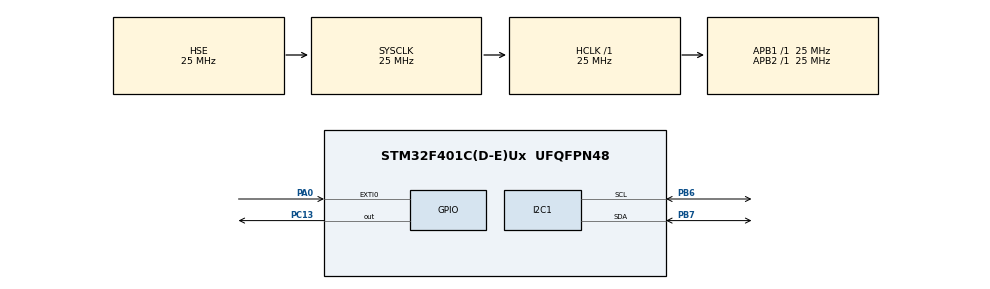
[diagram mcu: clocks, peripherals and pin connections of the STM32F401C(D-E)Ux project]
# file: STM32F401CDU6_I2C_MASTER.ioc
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Mcu.Family=STM32F4
Mcu.Name=STM32F401C(D-E)Ux
Mcu.Package=UFQFPN48
NVIC.EXTI0_IRQn=true\:0\:0\:false\:false\:true\:true\:true\:true
NVIC.I2C1_EV_IRQn=true\:0\:0\:false\:false\:true\:true\:true\:true
NVIC.PriorityGroup=NVIC_PRIORITYGROUP_4
PA0-WKUP.GPIO_ModeDefaultEXTI=GPIO_MODE_IT_RISING
PA0-WKUP.GPIO_PuPd=GPIO_PULLDOWN
PA0-WKUP.Signal=GPXTI0
PA13.Mode=Serial_Wire
PA13.Signal=SYS_JTMS-SWDIO
PA14.Mode=Serial_Wire
PA14.Signal=SYS_JTCK-SWCLK
PB6.Mode=I2C
PB6.Signal=I2C1_SCL
PB7.Mode=I2C
PB7.Signal=I2C1_SDA
PC13-ANTI_TAMP.PinState=GPIO_PIN_SET
PC13-ANTI_TAMP.Signal=GPIO_Output
PH0\ -\ OSC_IN.Mode=HSE-External-Oscillator
PH0\ -\ OSC_IN.Signal=RCC_OSC_IN
PH1\ -\ OSC_OUT.Mode=HSE-External-Oscillator
PH1\ -\ OSC_OUT.Signal=RCC_OSC_OUT
ProjectManager.HeapSize=0x200
ProjectManager.StackSize=0x400
ProjectManager.TargetToolchain=STM32CubeIDE
RCC.AHBFreq_Value=25000000
RCC.APB1Freq_Value=25000000
RCC.APB1TimFreq_Value=25000000
RCC.APB2Freq_Value=25000000
RCC.APB2TimFreq_Value=25000000
RCC.CortexFreq_Value=25000000
RCC.HCLKFreq_Value=25000000
RCC.HSE_VALUE=25000000
RCC.HSI_VALUE=16000000
RCC.LSE_VALUE=32768
RCC.SYSCLKFreq_VALUE=25000000
RCC.SYSCLKSource=RCC_SYSCLKSOURCE_HSE
RCC.VCOOutputFreq_Value=192000000
board=custom

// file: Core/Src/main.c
/* USER CODE BEGIN Header */
/**
  ******************************************************************************
  * @file           : main.c
  * @brief          : Main program body
  ******************************************************************************
  * @attention
  *
  * Copyright (c) 2024 STMicroelectronics.
  * All rights reserved.
  *
  * This software is licensed under terms that can be found in the LICENSE file
  * in the root directory of this software component.
  * If no LICENSE file comes with this software, it is provided AS-IS.
  *
  ******************************************************************************
  */
/* USER CODE END Header */
#include "main.h"

I2C_HandleTypeDef hi2c1;

/* USER CODE BEGIN PV */
static uint8_t data[] = {0x0F, 0x0A};  // Example data to send
static uint16_t DevAddress = 15 << 1;      // 7-bit address shifted for 8-bit format
static uint8_t index = 0;
/* USER CODE END PV */

void SystemClock_Config(void);
static void MX_GPIO_Init(void);
static void MX_I2C1_Init(void);

int main(void)
{

  /* MCU Configuration--------------------------------------------------------*/

  /* Reset of all peripherals, Initializes the Flash interface and the Systick. */
  HAL_Init();

  /* Configure the system clock */
  SystemClock_Config();

  /* Initialize all configured peripherals */
  MX_GPIO_Init();
  MX_I2C1_Init();

  /* Infinite loop */
  while (1)
  {

  }
}

void SystemClock_Config(void)
{
  RCC_OscInitTypeDef RCC_OscInitStruct = {0};
  RCC_ClkInitTypeDef RCC_ClkInitStruct = {0};

  /** Configure the main internal regulator output voltage
  */
  __HAL_RCC_PWR_CLK_ENABLE();
  __HAL_PWR_VOLTAGESCALING_CONFIG(PWR_REGULATOR_VOLTAGE_SCALE2);

  /** Initializes the RCC Oscillators according to the specified parameters
  * in the RCC_OscInitTypeDef structure.
  */
  RCC_OscInitStruct.OscillatorType = RCC_OSCILLATORTYPE_HSE;
  RCC_OscInitStruct.HSEState = RCC_HSE_ON;
  RCC_OscInitStruct.PLL.PLLState = RCC_PLL_NONE;
  if (HAL_RCC_OscConfig(&RCC_OscInitStruct) != HAL_OK)
  {
    Error_Handler();
  }

  /** Initializes the CPU, AHB and APB buses clocks
  */
  RCC_ClkInitStruct.ClockType = RCC_CLOCKTYPE_HCLK|RCC_CLOCKTYPE_SYSCLK
                              |RCC_CLOCKTYPE_PCLK1|RCC_CLOCKTYPE_PCLK2;
  RCC_ClkInitStruct.SYSCLKSource = RCC_SYSCLKSOURCE_HSE;
  RCC_ClkInitStruct.AHBCLKDivider = RCC_SYSCLK_DIV1;
  RCC_ClkInitStruct.APB1CLKDivider = RCC_HCLK_DIV1;
  RCC_ClkInitStruct.APB2CLKDivider = RCC_HCLK_DIV1;

  if (HAL_RCC_ClockConfig(&RCC_ClkInitStruct, FLASH_LATENCY_0) != HAL_OK)
  {
    Error_Handler();
  }
}

static void MX_I2C1_Init(void)
{

  hi2c1.Instance = I2C1;
  hi2c1.Init.ClockSpeed = 100000;
  hi2c1.Init.DutyCycle = I2C_DUTYCYCLE_2;
  hi2c1.Init.OwnAddress1 = 0;
  hi2c1.Init.AddressingMode = I2C_ADDRESSINGMODE_7BIT;
  hi2c1.Init.DualAddressMode = I2C_DUALADDRESS_DISABLE;
  hi2c1.Init.OwnAddress2 = 0;
  hi2c1.Init.GeneralCallMode = I2C_GENERALCALL_DISABLE;
  hi2c1.Init.NoStretchMode = I2C_NOSTRETCH_DISABLE;
  if (HAL_I2C_Init(&hi2c1) != HAL_OK)
  {
    Error_Handler();
  }

}

static void MX_GPIO_Init(void)
{
  GPIO_InitTypeDef GPIO_InitStruct = {0};

  /* GPIO Ports Clock Enable */
  __HAL_RCC_GPIOC_CLK_ENABLE();
  __HAL_RCC_GPIOH_CLK_ENABLE();
  __HAL_RCC_GPIOA_CLK_ENABLE();
  __HAL_RCC_GPIOB_CLK_ENABLE();

  /*Configure GPIO pin Output Level */
  HAL_GPIO_WritePin(GPIOC, GPIO_PIN_13, GPIO_PIN_SET);

  /*Configure GPIO pin : PC13 */
  GPIO_InitStruct.Pin = GPIO_PIN_13;
  GPIO_InitStruct.Mode = GPIO_MODE_OUTPUT_PP;
  GPIO_InitStruct.Pull = GPIO_NOPULL;
  GPIO_InitStruct.Speed = GPIO_SPEED_FREQ_LOW;
  HAL_GPIO_Init(GPIOC, &GPIO_InitStruct);

  /*Configure GPIO pin : PA0 */
  GPIO_InitStruct.Pin = GPIO_PIN_0;
  GPIO_InitStruct.Mode = GPIO_MODE_IT_RISING;
  GPIO_InitStruct.Pull = GPIO_PULLDOWN;
  HAL_GPIO_Init(GPIOA, &GPIO_InitStruct);

  /* EXTI interrupt init*/
  HAL_NVIC_SetPriority(EXTI0_IRQn, 0, 0);
  HAL_NVIC_EnableIRQ(EXTI0_IRQn);

}

/* USER CODE BEGIN 4 */
/* HAL callback function for EXTI line 0 (PA0) */
void HAL_GPIO_EXTI_Callback(uint16_t GPIO_Pin) {
    if (GPIO_Pin == GPIO_PIN_0) {
    	HAL_GPIO_TogglePin(GPIOC, GPIO_PIN_13);
    	index %= 2;
    	HAL_I2C_Master_Transmit(&hi2c1, DevAddress, (uint8_t*)data, (uint16_t)1, (uint16_t)1000);
    	HAL_Delay(2000);
    	index++;
    }
}
/* USER CODE END 4 */

void Error_Handler(void)
{
  __disable_irq();
  while (1)
  {
  }
}
